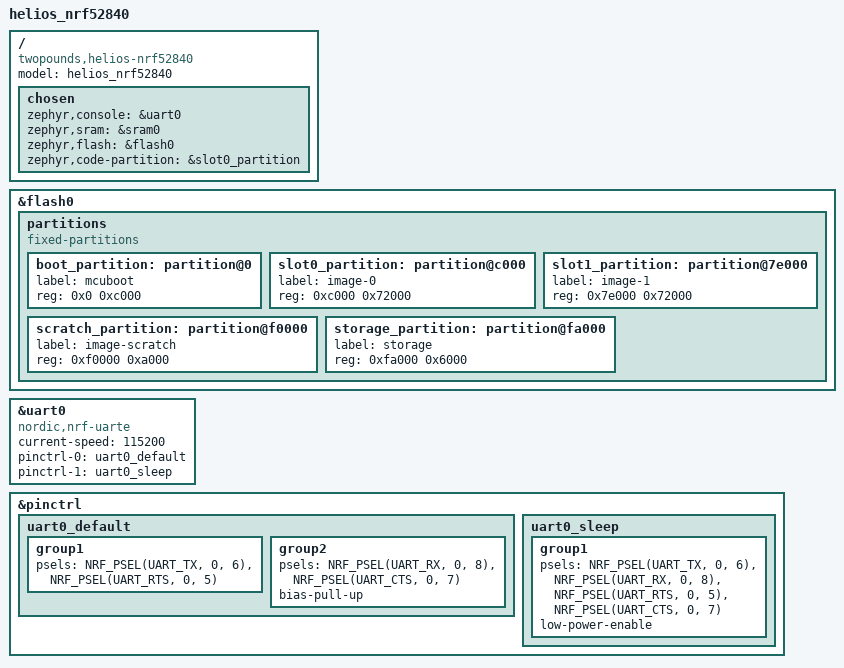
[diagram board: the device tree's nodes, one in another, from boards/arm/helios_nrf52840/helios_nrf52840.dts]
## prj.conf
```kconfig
#logging
CONFIG_LOG=y
CONFIG_LOG_DEFAULT_LEVEL=3
CONFIG_LOG_BACKEND_RTT=y
CONFIG_LOG_BACKEND_UART=n

#bluetooth
CONFIG_BT=y
CONFIG_BT_PERIPHERAL=y
CONFIG_BT_NUS=y
CONFIG_BT_DEVICE_NAME="Helios"
CONFIG_BT_MAX_CONN=1
CONFIG_BT_LL_SOFTDEVICE=y


#uart
CONFIG_UART_ASYNC_API=y
CONFIG_SERIAL=y

#adc
CONFIG_ADC=y

#increase bt throughput
#CONFIG_BT_GATT_CLIENT=y
#CONFIG_BT_BUF_ACL_RX_SIZE=251
#CONFIG_BT_BUF_ACL_TX_SIZE=251
#CONFIG_BT_L2CAP_TX_MTU=257
#CONFIG_BT_CTLR_DATA_LENGTH_MAX=251
#CONFIG_BT_CTLR_ADV_DATA_LEN_MAX=256
```

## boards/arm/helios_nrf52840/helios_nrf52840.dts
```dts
// Copyright (c) 2023 Nordic Semiconductor ASA
// SPDX-License-Identifier: Apache-2.0

/dts-v1/;
#include <nordic/nrf52840_qiaa.dtsi>

/ {
	model = "helios_nrf52840";
	compatible = "twopounds,helios-nrf52840";

	chosen {
		// zephyr,console = &cdc_acm_uart1; // original from manuel
		zephyr,console = &uart0; // inserted by jowi 5.9.2023
		zephyr,sram = &sram0;
		zephyr,flash = &flash0;
		zephyr,code-partition = &slot0_partition;
	};
};

//zephyr_udc0: &usbd {
//	compatible = "nordic,nrf-usbd";
//	status = "okay";
//	cdc_acm_uart1: cdc_acm_uart1 {
//		compatible = "zephyr,cdc-acm-uart";
//	};
//};


&flash0 {
	partitions {
		compatible = "fixed-partitions";
		#address-cells = <1>;
		#size-cells = <1>;

		boot_partition: partition@0 {
			label = "mcuboot";
			reg = <0x0 0xc000>;
		};
		slot0_partition: partition@c000 {
			label = "image-0";
			reg = <0xc000 0x72000>;
		};
		slot1_partition: partition@7e000 {
			label = "image-1";
			reg = <0x7e000 0x72000>;
		};
		scratch_partition: partition@f0000 {
			label = "image-scratch";
			reg = <0xf0000 0xa000>;
		};
		storage_partition: partition@fa000 {
			label = "storage";
			reg = <0xfa000 0x6000>;
		};
	};
};

&uart0 {
	compatible = "nordic,nrf-uarte";
	status = "okay";
	current-speed = <115200>;
	pinctrl-0 = <&uart0_default>;
	pinctrl-1 = <&uart0_sleep>;
	pinctrl-names = "default", "sleep";
};

&pinctrl {
	uart0_default: uart0_default {
		group1 {
			psels = <NRF_PSEL(UART_TX, 0, 6)>,
				<NRF_PSEL(UART_RTS, 0, 5)>;
		};
		group2 {
			psels = <NRF_PSEL(UART_RX, 0, 8)>,
				<NRF_PSEL(UART_CTS, 0, 7)>;
			bias-pull-up;
		};
	};

	uart0_sleep: uart0_sleep {
		group1 {
			psels = <NRF_PSEL(UART_TX, 0, 6)>,
				<NRF_PSEL(UART_RX, 0, 8)>,
				<NRF_PSEL(UART_RTS, 0, 5)>,
				<NRF_PSEL(UART_CTS, 0, 7)>;
			low-power-enable;
		};
	};
};
```

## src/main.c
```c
/*
 * Copyright (c) 2012-2014 Wind River Systems, Inc.
 *
 * SPDX-License-Identifier: Apache-2.0
 */

#include <zephyr/kernel.h>
#include <zephyr/bluetooth/bluetooth.h>
#include "serial.h"

void main(void)
{
	serial_enable(SERIAL_TYPE_ALL|SERIAL_TYPE_BLE);
	serial_set_end_character_list("\n", 1);
	serial_sendf(K_FOREVER, "Hello World!\n");
	
	while (true)
	{
		serial_line_t const * p_line = serial_get_line(K_FOREVER);
		serial_send(K_FOREVER, p_line->p_data, p_line->len);
		serial_sendf(K_FOREVER, "hallo welt\n");
	}
}
```
